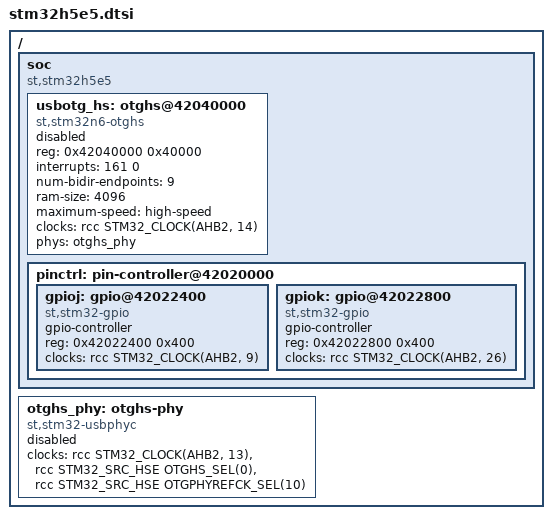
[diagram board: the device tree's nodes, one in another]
/*
 * Copyright (c) 2026 STMicroelectronics
 *
 * SPDX-License-Identifier: Apache-2.0
 */

#include <st/h5/stm32h5e4.dtsi>

/ {
	soc {
		compatible = "st,stm32h5e5", "st,stm32h5", "simple-bus";

		usbotg_hs: otghs@42040000 {
			compatible = "st,stm32n6-otghs", "st,stm32-otghs";
			reg = <0x42040000 0x40000>;
			interrupts = <161 0>;
			interrupt-names = "otghs";
			num-bidir-endpoints = <9>;
			ram-size = <4096>;
			maximum-speed = "high-speed";
			clocks = <&rcc STM32_CLOCK(AHB2, 14)>;
			phys = <&otghs_phy>;
			status = "disabled";
		};

		pinctrl: pin-controller@42020000 {
			gpioj: gpio@42022400 {
				compatible = "st,stm32-gpio";
				gpio-controller;
				#gpio-cells = <2>;
				reg = <0x42022400 0x400>;
				clocks = <&rcc STM32_CLOCK(AHB2, 9)>;
			};

			gpiok: gpio@42022800 {
				compatible = "st,stm32-gpio";
				gpio-controller;
				#gpio-cells = <2>;
				reg = <0x42022800 0x400>;
				clocks = <&rcc STM32_CLOCK(AHB2, 26)>;
			};
		};
	};

	otghs_phy: otghs-phy {
		/*
		 * This PHY is called "OTG_HS PHY" like on STM32U5 and STM32WBA series.
		 * However, the programming model is identical to "USBPHYC" found on
		 * STM32H7R/S series: PHY configuration is done through RCC registers.
		 * Reuse the H7R/S compatible as it matches our programming model even
		 * though "USBPHYC" is not used at all in the STM32H5E/F Reference Manual.
		 * The node name follows the RM terminology as it be chosen arbitrarily.
		 */
		compatible = "st,stm32-usbphyc";
		#phy-cells = <0>;
		clocks = <&rcc STM32_CLOCK(AHB2, 13)>,
			 <&rcc STM32_SRC_HSE OTGHS_SEL(0)>,
			 <&rcc STM32_SRC_HSE OTGPHYREFCK_SEL(10)>;
		clock-names = "gate", "mux", "fsel";
		status = "disabled";
	};
};
